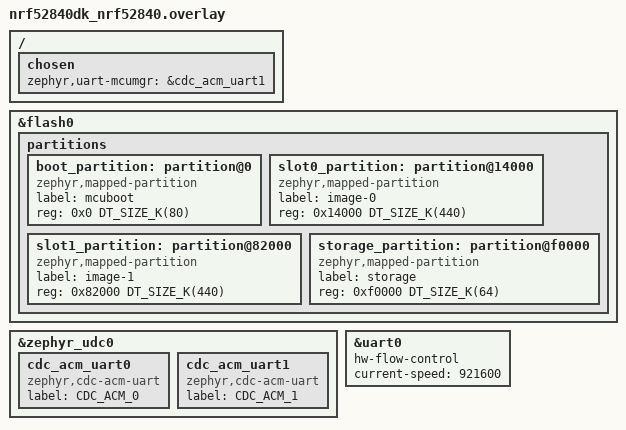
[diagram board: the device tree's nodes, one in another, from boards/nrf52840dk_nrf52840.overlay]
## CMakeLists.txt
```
# BLE bridge firmware (Task 9 data plane, Task 10 BLE central).
#
# Reuses the C frame library in ../proto (Task 6) verbatim via
# add_subdirectory(); only bridge_status_t was appended to bridge_proto.h.
#
# Pure-logic units (bridge_dispatch.c, bridge_info.c, bridge_ble_pure.c)
# deliberately include NO Zephyr headers - only the standard headers plus
# bridge_proto.h - so they compile as a standalone host target for
# host-side unit tests later (ADR-005 style):
#
#     cc -std=c11 -Wall -Wextra -I firmware/proto \
#        -c firmware/app/src/bridge_dispatch.c \
#        -c firmware/app/src/bridge_ble_pure.c \
#        -c firmware/app/src/bridge_info.c -c firmware/proto/bridge_proto.c

cmake_minimum_required(VERSION 3.20.0)

# ---- Bridge version, single bump point (D3, task-dfu-a report §9.5) -------
# BRIDGE_VERSION_STR is the ONE place to bump: "maj.min.rev[-suffix]".
#   - numeric maj.min.rev -> MCUboot image header version (imgtool --version,
#     "maj.min.rev+build": imgtool rejects non-numeric build counters, so a
#     pre-release suffix like "-dfu-test" rides in the ping string only);
#   - full string (suffix included) -> CONFIG_BRIDGE_VERSION (bridge ping
#     "blebridge<version>") through the APPVERSION Kconfig default.
# The injection happens at the Kconfig stage (env exported to kconfig.py by
# zephyr/cmake/modules/kconfig.cmake:156-159) because the signing script that
# finally reads CONFIG_MCUBOOT_IMGTOOL_SIGN_VERSION
# (nrf/cmake/sysbuild/image_signing.cmake:88) is included from INSIDE
# find_package(Zephyr) -> zephyr/CMakeLists.txt:2203; anything a CMakeLists
# sets after find_package is too late.  Upstream never exports the guard
# variable VERSION_MAJOR (zephyr/modules/Kconfig.mcuboot:111), which is why
# the imgtool-version default stayed "0.0.0+0" - exported here to engage it.
#
# NOTE: -DCONFIG_BRIDGE_VERSION=<s> still overrides the ping string alone
# (Kconfig CLI precedence) but then the ping string and the image header
# version decouple.  sysbuild does not forward arbitrary -D variables to the
# image builds, so the bump path is editing BRIDGE_VERSION_STR above (a
# non-sysbuild single-image `west build -DBRIDGE_VERSION_STR=...` works too).
set(BRIDGE_VERSION_STR "0.6.3" CACHE STRING
    "bridge version, maj.min.rev with optional -suffix")
string(REGEX MATCH "^([0-9]+)\\.([0-9]+)\\.([0-9]+)(-.*)?$"
       _bridge_semver "${BRIDGE_VERSION_STR}"
)
if(NOT _bridge_semver)
  message(FATAL_ERROR
    "BRIDGE_VERSION_STR (\"${BRIDGE_VERSION_STR}\") must be numeric "
    "maj.min.rev with an optional -suffix (D3: it also forms the MCUboot "
    "image header version)."
  )
endif()
set(APP_VERSION_STRING "${BRIDGE_VERSION_STR}")
set(APP_VERSION_TWEAK_STRING
    "${CMAKE_MATCH_1}.${CMAKE_MATCH_2}.${CMAKE_MATCH_3}+0")
set(ENV{VERSION_MAJOR} "${CMAKE_MATCH_1}")

find_package(Zephyr REQUIRED HINTS $ENV{ZEPHYR_BASE})
project(bridge_bridge LANGUAGES C)

set(BRIDGE_PROTO_DIR ${CMAKE_CURRENT_SOURCE_DIR}/../proto)
add_subdirectory(${BRIDGE_PROTO_DIR} proto_build)

target_link_libraries(app PRIVATE bridge_proto)
target_include_directories(app PRIVATE src)

target_sources(app PRIVATE
  src/main.c
  src/bridge_phy.c
  src/bridge_link.c
  src/bridge_dispatch.c
  src/bridge_info.c
  src/bridge_ble.c
  src/bridge_ble_pure.c
  src/bridge_periph.c
)

# BRIDGE_PHY is a string Kconfig ("cdc" | "uart0"); map it onto a single
# compile definition so the C sources can select at compile time (C
# preprocessor cannot compare strings).
if(CONFIG_BRIDGE_PHY STREQUAL "uart0")
  target_compile_definitions(app PRIVATE BRIDGE_PHY_MODE_UART0=1)
else()
  if(NOT CONFIG_BRIDGE_PHY STREQUAL "cdc")
    message(FATAL_ERROR "CONFIG_BRIDGE_PHY must be \"cdc\" or \"uart0\", got \"${CONFIG_BRIDGE_PHY}\"")
  endif()
  target_compile_definitions(app PRIVATE BRIDGE_PHY_MODE_CDC=1)
endif()

# Self-imposed warning hygiene for the new sources (Zephyr already adds
# -Wall; -Wextra is our own bar for this app).
target_compile_options(app PRIVATE -Wall -Wextra)

# NOTE for anyone trying to set CONFIG_MCUBOOT_IMGTOOL_SIGN_VERSION here
# (after find_package): that CMake variable is consumed by the signing script
# while find_package(Zephyr) is still running (see the version block at the
# top of this file for the working injection point and the full story).
```

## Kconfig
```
# BLE bridge firmware application options (Task 9).

mainmenu "BLE bridge firmware"

menu "bridge options"

config BRIDGE_PHY
	string "bridge physical layer"
	default "cdc"
	help
	  "cdc"   = nRF52840 native USB CDC ACM on zephyr_udc0 (primary,
	            ADR-002 revision 1; bit rate is negotiated by USB).
	  "uart0" = DK UART0 at 921600 8N1 with RTS/CTS hardware flow
	            control (backup, external adapter; pins P0.06/P0.08/
	            P0.05/P0.07 as wired by the nrf52840dk board files).
	  Anything else fails the CMake configure step.

config BRIDGE_VERSION
	string "bridge semantic version (ping body is blebridge<version>)"
	default "$(APPVERSION)"
	help
	  Derived from BRIDGE_VERSION_STR in CMakeLists.txt (the single bump
	  point, D3): the Kconfig environment exports APPVERSION from it at
	  configure time.  Bump the CMake variable, not this default.

config BRIDGE_CREDITS_INIT
	int "initial event credit balance (host grants more via CMD.credits)"
	default 128

config BRIDGE_LOG_LEVEL
	int "initial log level for EVT.DEBUG gating (0=off 1=err 2=warn 3=info 4=debug)"
	default 3
	range 0 4

config BRIDGE_USB_DTR_WAIT_MS
	int "max wait at boot for CDC ACM DTR before starting (ms)"
	default 5000

config BRIDGE_EVENT_PAYLOAD_MAX
	int "largest event payload accepted by bridge_link_post_event (bytes)"
	default 256

config BRIDGE_EVENT_QUEUE_LEN
	int "depth of the ISR-safe event queue feeding the event thread"
	default 16

config BRIDGE_TX_QUEUE_LEN
	int "depth of the TX frame queue drained by the single TX thread"
	default 8

config BRIDGE_CONNECT_TIMEOUT_MS
	int "max wait for CMD.connect to establish the link (ms)"
	default 5000

config BRIDGE_PAIR_TIMEOUT_MS
	int "max wait for CMD.pair to complete SMP pairing (ms)"
	default 8000
	range 500 30000

config BRIDGE_SCAN_DURATION_MS
	int "scan window used by CMD.scan_start when the request says 0 (ms)"
	default 8000
	range 100 60000

config BRIDGE_SCAN_FILTER_FEF5
	bool "EVT.SCAN reports only adverts carrying 0xFEF5 service data"
	default n
	help
	  Default off: every advert is reported and the host filters (daemon
	  keeps the dedup-by-addr view).  Turn on for a quiet wire.

config BRIDGE_SCAN_CACHE_SIZE
	int "scan result cache entries (connect-by-name lookups)"
	default 8
	range 1 64

config BRIDGE_GATT_CHAR_MAX
	int "characteristics cached per link across host-triggered discoveries"
	default 32
	range 1 32
	help
	  Entries of the GATT map filled by CMD.disc_svc (one run per service,
	  merged until the link drops; each characteristic's CCC descriptor
	  rides along inside its entry).  The SUOTA service needs 10; a
	  generic multi-service device wants headroom.

config BRIDGE_ADV_NAME
	string "local device name used by CMD.adv_start (FR-H)"
	default "blebridge"

config BRIDGE_ADV_INTERVAL_DEFAULT_MS
	int "advertising interval (ms) used by CMD.adv_start when the request sends 0xFFFF"
	default 100
	range 20 10240

config BRIDGE_ADV_AUTO_RESTART
	bool "automatically restart advertising after the peripheral link drops (FR-H fix round 1)"
	default y
	help
	  The advertising intent survives a lost peripheral link: a clean
	  disconnect or a crashed peer re-starts the last advertising
	  configuration when CMD.adv_start was in effect.  Only an explicit
	  CMD.adv_stop silences the auto-restart (real-device finding
	  2026-09-25: every link loss otherwise required a manual adv-start).

config BRIDGE_GATT_DYN_SVCS
	int "host-defined GATT service slots (CMD.gatt_define, FR-H5)"
	default 4
	range 1 8

config BRIDGE_GATT_DYN_CHARS_MAX
	int "characteristics per host-defined GATT service (CMD.gatt_define)"
	default 8
	range 1 8

config BRIDGE_GATT_DYN_SVC_POOL
	int "value-storage bytes per host-defined GATT service slot"
	default 1024
	range 64 4096
	help
	  Sum of all characteristic max_len values of ONE gatt_define
	  service; the definition is rejected when the request exceeds it.

config BRIDGE_CONFIRM_DELAY_MS
	int "stable-uptime milliseconds required before image self-confirm"
	default 10000
	range 1000 600000
	help
	  The confirm thread (main.c) waits this long after boot, checks the
	  bridge health counters, and only then calls
	  boot_write_img_confirmed().  An image that crashes or wedges before
	  the deadline never confirms, so the next reset makes MCUboot swap
	  back to the previous slot (revert).  Keep this well above any
	  plausible boot-time failure window but short enough that a normal
	  boot confirms without host interaction.

config BRIDGE_CONFIRM_THREAD_STACK
	int "stack bytes for the self-confirm thread"
	default 1024
	range 512 8192

endmenu

source "Kconfig.zephyr"
```

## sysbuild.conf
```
# Self-OTA (task-dfu-a): sysbuild + MCUboot dual-slot baseline.
#
# Eval report docs/reports/dfu-usbcdc-eval-20260926.md §6.1.  Enabling the
# bootloader switches the build to NCS sysbuild mode.  Partition freeze,
# NCS v3.4.1 finding: on nrf52840dk this NCS does NOT engage the Nordic
# partition manager -- the layout comes from the devicetree fixed
# partitions (zephyr/dts/vendor/nordic/nrf52840_partition.dtsi).  The
# reproducible "frozen" layout is therefore the committed overlay pair
#   - boards/nrf52840dk_nrf52840.overlay  (app; sysbuild.conf also makes
#     a plain `west build` a sysbuild build, so this map covers ALL builds)
#   - sysbuild/mcuboot.overlay            (bootloader, same map)
# which must stay byte-consistent; see those files for the measured 48K vs
# 80K decision (serial recovery needs ~60 KiB).
#
# Upgrade mode: MCUBOOT_MODE_SWAP_USING_MOVE (the NCS choice default in
# nrf/sysbuild/Kconfig.mcuboot; sibling of swap-using-scratch/offset).  Both
# non-scratch swap modes keep the "trial + confirm + revert" semantics that
# is the brick-proof core: an unconfirmed image is swapped back by MCUboot
# on the next reset.  nRF52840 has uniform 4 KB pages (nrf52840.dtsi
# erase-block-size), which satisfies the homogeneous-page requirement of
# offset/move; no scratch partition is needed.  Kept at the default instead
# of pinning a mode: the default tracks NCS recommendations across releases.
# (Verified in build-dfu/mcuboot/zephyr/.config: BOOT_SWAP_USING_MOVE=y,
# SINGLE_APPLICATION_SLOT unset, UPDATEABLE_IMAGE_NUMBER=1.)
#
# Signature: BOOT_SIGNATURE_TYPE_ECDSA_P256 is already the sysbuild default
# for nRF52840 (nrf/sysbuild/Kconfig.mcuboot BOOT_SIGNATURE_TYPE choice).
# The signing key is user-generated (NOT committed; see ci/keys/ -- generate
# with: openssl ecparam -name prime256v1 -genkey -noout -out <key>.pem).
# The key path must be absolute or relative to the app config dir /
# west topdir (zephyr/cmake/mcuboot.cmake resolution order), so tools/
# build-dfu.sh injects it as an absolute -DSB_CONFIG_BOOT_SIGNATURE_KEY_FILE.
# A plain `west build` without that flag falls back to the MCUboot tree's
# root-ec-p256.pem test key: the build succeeds but the images would not be
# verifiable by a bootloader built with your key -- always build
# through tools/build-dfu.sh for anything that gets flashed.
SB_CONFIG_BOOTLOADER_MCUBOOT=y
# One merged hex per board target (mcuboot + app slots): the artifact
# WCH-Link/pyocd flashes for the whole-image bring-up.
SB_CONFIG_MERGED_HEX_FILES=y
```

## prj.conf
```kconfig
# BLE bridge firmware (Task 9 data plane, Task 10 BLE central) - nrf52840dk/nrf52840
#
# Data plane: USB CDC ACM (primary) / UART0 (backup), framing + dispatch +
# credit flow control.  Zephyr LOG is intentionally OFF: the bridge has its
# own EVT.DEBUG log channel on the protocol stream.

CONFIG_SERIAL=y
CONFIG_UART_INTERRUPT_DRIVEN=y
CONFIG_UART_LINE_CTRL=y
CONFIG_RING_BUFFER=y

# CMD.reset performs sys_reboot(SYS_REBOOT_COLD) after the best-effort ACK.
CONFIG_REBOOT=y

# Native USB device stack (new stack, Zephyr 4.x) + CDC ACM class.
CONFIG_USB_DEVICE_STACK_NEXT=y
CONFIG_USBD_CDC_ACM_CLASS=y
CONFIG_CDC_ACM_SERIAL_INITIALIZE_AT_BOOT=n
CONFIG_HWINFO=y

# The protocol stream owns cdc_acm_uart0 end to end: no Zephyr
# console/printk sink and no LOG subsystem on the same UART (the bridge's
# log channel is EVT.DEBUG on the protocol stream itself).  Threads are the
# whole app.
# task-dfu-a: CONFIG_CONSOLE flips to y because MCUMGR_TRANSPORT_UART
# depends on CONSOLE (zephyr/subsys/mgmt/mcumgr/transport/Kconfig.uart:20).
# UART_CONSOLE stays n -- no console backend attaches anywhere, so nothing
# ever writes to either CDC port except the bridge protocol (port 0) and
# the SMP transport (port 1); the flip is a dependency formality verified
# by the crosstalk regression in the task report.
CONFIG_CONSOLE=y
CONFIG_UART_CONSOLE=n
CONFIG_LOG=n
CONFIG_MULTITHREADING=y

# Skeleton hygiene: asserts on, thread names for debugging, hex artifact
# for the build gate report.CONFIG_ASSERT=y
CONFIG_THREAD_NAME=y
CONFIG_BUILD_OUTPUT_HEX=y

# ---- BLE central (Task 10; symbol names verified against NCS v3.4.1) ----
CONFIG_BT=y
CONFIG_BT_CENTRAL=y
# FR-H multi-role: 1 central (host-initiated device link) + 1 peripheral
# (phone/tool connecting to the bridge's own services) concurrently.
CONFIG_BT_MAX_CONN=2

# ---- BLE peripheral (FR-H) ----
# GATT server role: the preset 0xFFE0 test service (compile-time) plus
# host-defined services via CMD.gatt_define (runtime registration).
CONFIG_BT_PERIPHERAL=y
CONFIG_BT_GATT_DYNAMIC_DB=y

# GATT client operations + automatic ATT MTU exchange on connect (works for
# the central role too; verified against NCS v3.4.1 / Zephyr 4.4.2).
CONFIG_BT_GATT_CLIENT=y
CONFIG_BT_GATT_AUTO_UPDATE_MTU=y

# 244-byte characteristic payloads: local ATT MTU halves are
#   TX = CONFIG_BT_L2CAP_TX_MTU (247)
#   RX = CONFIG_BT_BUF_ACL_RX_SIZE - 4 (247)
# and the buffers must carry the 4-byte L2CAP header + 247 ATT bytes.
CONFIG_BT_L2CAP_TX_MTU=247
CONFIG_BT_BUF_ACL_TX_SIZE=251
CONFIG_BT_BUF_ACL_RX_SIZE=251

# Buffer counts: 244-byte notify bursts arrive as up to 10 ACL fragments;
# defaults (TX 3) would congest.  RX pool = BT_MAX_CONN + 1 + EXTRA.
# HCI event buffers must stay above the ACL TX count (build-time assert).
CONFIG_BT_BUF_ACL_TX_COUNT=10
CONFIG_BT_BUF_ACL_RX_COUNT_EXTRA=6
CONFIG_BT_BUF_EVT_RX_COUNT=12

# Data Length Update + 2M PHY on connect (central preference; SDC has no
# separate "enable 2M" switch - docs/research/nordic-stack-eval.md).
CONFIG_BT_DATA_LEN_UPDATE=y
CONFIG_BT_AUTO_DATA_LEN_UPDATE=y
CONFIG_BT_PHY_UPDATE=y
CONFIG_BT_AUTO_PHY_CENTRAL_2M=y
CONFIG_BT_USER_PHY_UPDATE=y

# Nordic GATT Discovery Manager (NCS): 0xFEF5 discovery at connect.  Runs
# on the system workqueue (saves the dedicated workq thread), map sized for
# the SUOTA service.
CONFIG_BT_GATT_DM=y
CONFIG_BT_GATT_DM_WORKQ_SYS=y
CONFIG_BT_GATT_DM_MAX_ATTRS=64

# bt_gatt_dm allocates the discovered attr array from the system heap, but
# the module only adds 512B of its own (HEAP_MEM_POOL_ADD_SIZE_BT_GATT_DM).
# A full 0xFEF5 service (~25 attrs) needs more: with the default heap of
# 0 the dm fails with -ENOMEM (-12) exactly when the service IS found
# (random devices without 0xFEF5 mask this - bring-up 2026-09-25).
CONFIG_HEAP_MEM_POOL_SIZE=4096

# Host create timeout must bracket CONFIG_BRIDGE_CONNECT_TIMEOUT_MS (5 s).
CONFIG_BT_CREATE_CONN_TIMEOUT=5

# ---- SMP pairing/encryption (FR-B5) ----
# Session-scoped LE pairing so the host can raise the link to L2 (Just Works:
# the stack reports NoInputNoOutput when no auth callbacks provide IO -- smp.c
# get_io_capa(); unauthenticated pairing, L2 encryption only).
CONFIG_BT_SMP=y
# Bond persistence (settings/FS) is deliberately out of FR-B5 scope: keys live
# in RAM for the session only; a serial CMD.reset drops them.  (Explicit over
# implicit: default is n; flipping it later needs SETTINGS + an NVS backend.)
CONFIG_BT_SETTINGS=n
# FR-H peripheral likewise runs unencrypted/unpaired: the test services are
# plain-text by design (no bond, no SETTINGS backend needed).

# ---- Self-OTA infrastructure (task-dfu-a) --------------------------------
# CONFIG_BOOTLOADER_MCUBOOT is intentionally NOT set here: sysbuild injects
# it into the app image when SB_CONFIG_BOOTLOADER_MCUBOOT=y
# (zephyr/share/sysbuild/image_configurations/MAIN_image_default.cmake:8),
# and setting it unconditionally would wrongly header-offset the legacy
# single-slot flow (tools/flash.sh) which links at 0x0 without a
# bootloader.  The dual-slot partition map (80K bootloader variant) lives
# in boards/nrf52840dk_nrf52840_dfu80.overlay, applied by build-dfu.sh.
# IMG_MANAGER depends on STREAM_FLASH (zephyr/subsys/dfu/Kconfig:8) and
# MCUBOOT_IMG_MANAGER depends on FLASH_MAP -- all requested explicitly,
# exactly like the smp_svr authority sample (FLASH=y is also its first
# entry; omitting it makes STREAM_FLASH_INSPECT y-select FLASH_PAGE_LAYOUT
# whose FLASH dependency fails -> Kconfig warning-as-error).
CONFIG_FLASH=y
CONFIG_STREAM_FLASH=y
CONFIG_FLASH_MAP=y
CONFIG_IMG_MANAGER=y
CONFIG_IMG_ERASE_PROGRESSIVELY=y

# MCUmgr SMP over the second CDC ACM (zephyr,uart-mcumgr = &cdc_acm_uart1).
# Transport deps (Kconfig.uart): CONSOLE (flipped above), BASE64, CRC,
# UART_MCUMGR.  Auth is deliberately absent (intratable internal tool on a
# lab USB link; the group set below is image upload/test/confirm + os
# reset -- the minimum for the DFU loop).
CONFIG_UART_MCUMGR=y
# MCUMGR depends on NET_BUF + ZCBOR (subsys/mgmt/mcumgr/Kconfig:7-8);
# both explicit like the smp_svr authority sample.
CONFIG_NET_BUF=y
CONFIG_ZCBOR=y
CONFIG_MCUMGR=y
CONFIG_MCUMGR_TRANSPORT_UART=y
# Frame MTU 1024 (<= MCUMGR_TRANSPORT_NETBUF_SIZE+2; NETBUF raised from the
# 384 default so the relation holds).  4 netbufs x 1024 B ~= 4 KB RAM.
CONFIG_MCUMGR_TRANSPORT_UART_MTU=1024
CONFIG_MCUMGR_TRANSPORT_NETBUF_SIZE=1024
CONFIG_BASE64=y
CONFIG_CRC=y
CONFIG_MCUMGR_GRP_IMG=y
CONFIG_MCUMGR_GRP_OS=y

# Application self-confirmation: RETENTION_BOOT_MODE exposes bootmode_set()
# for CMD.enter_dfu (GPREGRET -> MCUboot serial recovery); the chosen
# zephyr,boot-mode node lives in the board file (boot_mode0 under gpregret1).
# Dependency chain to spell out (all three, or the tail silently drops to n):
# RETAINED_MEM -> RETENTION -> RETENTION_BOOT_MODE; the GPREGRET retained-mem
# driver defaults on once RETAINED_MEM is y (DT_HAS_NORDIC_NRF_GPREGRET).
CONFIG_RETAINED_MEM=y
CONFIG_RETENTION=y
CONFIG_RETENTION_BOOT_MODE=y

# The confirm thread (main.c) waits BRIDGE_CONFIRM_DELAY_MS of stable
# uptime, checks bridge health counters, then boot_write_img_confirmed().
# A image that dies before that point is reverted by MCUboot on reset.
CONFIG_MAIN_STACK_SIZE=3072
CONFIG_BRIDGE_CONFIRM_DELAY_MS=10000
CONFIG_BRIDGE_CONFIRM_THREAD_STACK=1024
```

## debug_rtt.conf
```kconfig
# Bring-up diagnostics: Zephyr log over SEGGER RTT (SWD), does not touch UART0 pins.
# 用法: 构建 -DEXTRA_CONF_FILE=<repo>/firmware/app/debug_rtt.conf;
#       烧录 pyocd flash -e sector -t nrf52840 -f 1000000 <hex>（WCH-Link 限 1MHz SWD）。
CONFIG_LOG=y
CONFIG_LOG_MODE_MINIMAL=y
CONFIG_USE_SEGGER_RTT=y
CONFIG_RTT_CONSOLE=y
CONFIG_CONSOLE=y
```

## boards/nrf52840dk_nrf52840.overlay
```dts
/*
 * blebridge bridge overlay for nrf52840dk/nrf52840 (Task 9, rev. task-dfu-a).
 *
 * - zephyr_udc0 (native nRF52840 USB device, already status-okay in the
 *   board file) gains the CDC ACM UART class instance: the primary
 *   physical layer, selected with CONFIG_BRIDGE_PHY="cdc".
 * - task-dfu-a: a second CDC ACM instance (cdc_acm_uart1) serves the
 *   MCUmgr SMP transport, chosen via zephyr,uart-mcumgr (A1 dual-CDC
 *   architecture, docs/reports/dfu-usbcdc-eval-20260926.md §3.1).  The
 *   bridge protocol keeps owning cdc_acm_uart0 end to end; the SMP
 *   transport binds cdc_acm_uart1 exclusively (smp_uart.c), so the two
 *   streams cannot cross-contaminate.  macOS enumerates the pair as two
 *   /dev/cu.usbmodem* ports (same device, interface 0 = bridge, 1 = SMP).
 * - task-dfu-a: DFU dual-slot partition map, 80 KB bootloader variant.
 *   Lives HERE (not a build-flag overlay) because sysbuild.conf makes
 *   EVERY build of this app a sysbuild build (auto-detected: plain
 *   `west build` produces _sysbuild + dfu_application.zip), so there is
 *   no single-slot consumer left and one map for all builds is the only
 *   way to keep ad-hoc flashes consistent with the on-board bootloader.
 *   Sizes = official smp_svr "larger_mcuboot" layout: measured
 *   MCUboot-with-serial-recovery is 60.1 KiB and does NOT fit the stock
 *   48 KB boot partition (eval report §3.2 risk, resolved by measurement).
 *   The bootloader child declares the IDENTICAL map in
 *   sysbuild/mcuboot.overlay -- the two files must never diverge (each
 *   image derives slot ends / swap trailers from its own devicetree).
 * - uart0 is reconfigured to 921600 8N1 with RTS/CTS hardware flow
 *   control as the backup physical layer (CONFIG_BRIDGE_PHY="uart0").
 *   The board pinctrl already maps TX=P0.06 RX=P0.08 RTS=P0.05 CTS=P0.07.
 *   Bit rate only matters in uart0 mode; USB negotiates its own speed.
 */

/delete-node/ &boot_partition;
/delete-node/ &slot0_partition;
/delete-node/ &slot1_partition;
/delete-node/ &storage_partition;

&flash0 {
	partitions {
		boot_partition: partition@0 {
			compatible = "zephyr,mapped-partition";
			label = "mcuboot";
			reg = <0x0 DT_SIZE_K(80)>;
		};

		slot0_partition: partition@14000 {
			compatible = "zephyr,mapped-partition";
			label = "image-0";
			reg = <0x14000 DT_SIZE_K(440)>;
		};

		slot1_partition: partition@82000 {
			compatible = "zephyr,mapped-partition";
			label = "image-1";
			reg = <0x82000 DT_SIZE_K(440)>;
		};

		storage_partition: partition@f0000 {
			compatible = "zephyr,mapped-partition";
			label = "storage";
			reg = <0xf0000 DT_SIZE_K(64)>;
		};
	};
};

/* The cdc_acm_uart1 phandle is referenced by the chosen below; declare it
 * "cdc_acm_uart1: cdc_acm_uart1" (label + name), like the smp_svr
 * usb.overlay authority does for its CDC node. */

&zephyr_udc0 {
	status = "okay";

	cdc_acm_uart0: cdc_acm_uart0 {
		compatible = "zephyr,cdc-acm-uart";
		label = "CDC_ACM_0";
	};

	cdc_acm_uart1: cdc_acm_uart1 {
		compatible = "zephyr,cdc-acm-uart";
		label = "CDC_ACM_1";
	};
};

/ {
	chosen {
		zephyr,uart-mcumgr = &cdc_acm_uart1;
	};
};

&uart0 {
	hw-flow-control;
	current-speed = <921600>;
};
```

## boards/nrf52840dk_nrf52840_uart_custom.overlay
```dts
/*
 * blebridge bridge — 用户自定义 UART0 引脚 overlay（nrf52840dk/nrf52840）。
 *
 * 背景: 固件跑在 nrf52840dk/nrf52840 目标码上，但实际载板为用户自制板，
 * UART0 不走 DK 原生排布，而是走 P1 口。映射逐字采用用户选定的引脚:
 *
 *   信号  引脚    对应 DK 默认（boards/nrf52840dk_nrf52840.overlay /
 *                       板级 pinctrl dtsi）
 *   TX   = P1.04  (DK: P0.06)
 *   RX   = P1.13  (DK: P0.08)
 *   RTS  = P1.15  (DK: P0.05)
 *   CTS  = P1.00  (DK: P0.07)
 *
 * 速率/模式与 DK 默认路径一致: 921600 8N1 + RTS/CTS 硬件流控
 * （备用物理层，CONFIG_BRIDGE_PHY="uart0" 时启用）。
 *
 * 偏置选择（用户板上下文）:
 *   RX  bias-pull-up   —— 对端未接线/未上电时 RX 空闲保持高（UART 空闲电平）。
 *   CTS bias-pull-down —— CTS 悬空时读低 = 允许发送: 为 2 线（仅 TX/RX）
 *                         升级路径留门，不接流控线也能发。
 *
 * 使用: app 目标构建时附加
 *   -DEXTRA_DTC_OVERLAY_FILE=boards/nrf52840dk_nrf52840_uart_custom.overlay
 * 或 tools/flash.sh app --uart-custom（独立 build-t10-uart-custom 目录）。
 * 不修改、不影响 DK 默认 overlay（boards/nrf52840dk_nrf52840.overlay，
 * P0.06/08/05/07）—— 默认构建/HIL 不带本文件时行为与原先完全一致。
 */

&pinctrl {
	uart0_default_alt: uart0_default_alt {
		group1 {
			psels = <NRF_PSEL(UART_TX, 1, 4)>,
				<NRF_PSEL(UART_RTS, 1, 15)>;
		};

		group2 {
			psels = <NRF_PSEL(UART_RX, 1, 13)>;
			bias-pull-up;
		};

		group3 {
			psels = <NRF_PSEL(UART_CTS, 1, 0)>;
			bias-pull-down;
		};
	};

	uart0_sleep_alt: uart0_sleep_alt {
		group1 {
			psels = <NRF_PSEL(UART_TX, 1, 4)>,
				<NRF_PSEL(UART_RX, 1, 13)>,
				<NRF_PSEL(UART_RTS, 1, 15)>,
				<NRF_PSEL(UART_CTS, 1, 0)>;
			low-power-enable;
		};
	};
};

&uart0 {
	pinctrl-0 = <&uart0_default_alt>;
	pinctrl-1 = <&uart0_sleep_alt>;
	pinctrl-names = "default", "sleep";
	hw-flow-control;
	current-speed = <921600>;
};
```

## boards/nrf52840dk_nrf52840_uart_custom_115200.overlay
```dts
/*
 * blebridge bridge — bring-up 变体: 用户自定义 UART 引脚 @ 115200 8N1 + RTS/CTS。
 *
 * 与 nrf52840dk_nrf52840_uart_custom.overlay（产品速率 921600, FR-A5）唯一的
 * 差别是 current-speed = <115200>。存在理由（2026-09-25 bring-up 实测）:
 * 当前唯一 host 通路是 WCH-Link 的 CDC UART 桥,其 921600 RX 方向对 >64 B
 * 长突发不可靠（字节丢失/乱序, ≤64 B 帧始终完好）,长帧 CRC 无法通过;
 * 115200 下长帧 CRC 全部通过。待 host 通路更换或桥固件验证 921600 后,
 * 产品配置仍回到 921600 overlay。
 *
 * 引脚与偏置逐字沿用产品 overlay:
 *   TX=P1.04 (pull 无)  RX=P1.13 (pull-up)
 *   RTS=P1.15           CTS=P1.00 (pull-down, 悬空=允许发送)
 *
 * 使用（独立 build 目录, 不污染产品构建）:
 *   west build -p -b nrf52840dk/nrf52840 <app> -d <scratch> -- \
 *       '-DCONFIG_BRIDGE_PHY="uart0"' \
 *       -DEXTRA_DTC_OVERLAY_FILE=<repo>/firmware/app/boards/nrf52840dk_nrf52840_uart_custom_115200.overlay \
 *       -DEXTRA_CONF_FILE=<repo>/firmware/app/debug_rtt.conf
 * 烧录: pyocd flash -e sector -t nrf52840 -f 1000000 <hex>（WCH-Link 限 1MHz SWD）
 * host: SerialTransport(baudrate=115200, rtscts=False)（macOS CDC 上
 *       rtscts=True 会静默扣发 write; 开端口首帧会被桥毛刺打坏,需重试）
 */

&pinctrl {
	uart0_default_alt: uart0_default_alt {
		group1 {
			psels = <NRF_PSEL(UART_TX, 1, 4)>,
				<NRF_PSEL(UART_RTS, 1, 15)>;
		};

		group2 {
			psels = <NRF_PSEL(UART_RX, 1, 13)>;
			bias-pull-up;
		};

		group3 {
			psels = <NRF_PSEL(UART_CTS, 1, 0)>;
			bias-pull-down;
		};
	};

	uart0_sleep_alt: uart0_sleep_alt {
		group1 {
			psels = <NRF_PSEL(UART_TX, 1, 4)>,
				<NRF_PSEL(UART_RX, 1, 13)>,
				<NRF_PSEL(UART_RTS, 1, 15)>,
				<NRF_PSEL(UART_CTS, 1, 0)>;
			low-power-enable;
		};
	};
};

&uart0 {
	pinctrl-0 = <&uart0_default_alt>;
	pinctrl-1 = <&uart0_sleep_alt>;
	pinctrl-names = "default", "sleep";
	hw-flow-control;
	current-speed = <115200>;
};
```

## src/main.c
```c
/*
 * main.c - BLE bridge firmware entry point (Task 9 data plane,
 * Task 10 BLE central, task-dfu-a self-confirm).
 *
 * Bring-up order: physical layer -> BLE stack (bt_enable before the link
 * threads exist, so no command can outrun it; on failure the data plane
 * still comes up and the BLE family answers ERR_NOT_READY) -> link threads
 * -> boot EVT.DEBUG on the "sys" namespace -> confirm thread.
 *
 * Self-confirm (task-dfu-a): the confirm thread waits
 * CONFIG_BRIDGE_CONFIRM_DELAY_MS of stable uptime, takes the bridge health
 * snapshot and only then calls boot_write_img_confirmed().  MCUboot booted
 * this image as an unconfirmed "test" swap; if the image dies (or was
 * never healthy) before the confirm, the next reset swaps back to the
 * previous slot -- the brick-proof core of the A1+B architecture
 * (docs/reports/dfu-usbcdc-eval-20260926.md §4).
 */

#include <stdbool.h>
#include <stdio.h>

#include <zephyr/kernel.h>
#include <zephyr/dfu/mcuboot.h>

#include "bridge_ble.h"
#include "bridge_dispatch.h"
#include "bridge_link.h"
#include "bridge_phy.h"

#define CONFIRM_POLL_MS 1000

/* Latched in main() before the confirm thread starts: read-only for the
 * thread afterwards, no locking needed. */
static bool bringup_ok;

static K_THREAD_STACK_DEFINE(confirm_stack,
                             CONFIG_BRIDGE_CONFIRM_THREAD_STACK);
static struct k_thread confirm_thread;

static void confirm_thread_fn(void *a, void *b, void *c)
{
    ARG_UNUSED(a);
    ARG_UNUSED(b);
    ARG_UNUSED(c);

    const uint32_t min_uptime_s =
        (uint32_t)(CONFIG_BRIDGE_CONFIRM_DELAY_MS / 1000);

    for (;;) {
        k_sleep(K_MSEC(CONFIRM_POLL_MS));

        bool init_ok;
        uint32_t crc_errors;
        uint32_t tx_timeouts;
        uint32_t events_dropped;

        bridge_link_confirm_snapshot(&init_ok, &crc_errors, &tx_timeouts,
                                     &events_dropped);
        if (!init_ok) {
            init_ok = bringup_ok;
        }

        if (!bridge_confirm_ready((uint32_t)(k_uptime_get_32() / 1000U),
                                  min_uptime_s, init_ok, crc_errors,
                                  tx_timeouts, events_dropped)) {
            continue;
        }

        if (boot_is_img_confirmed()) {
            /* Reconfirmed boot of an already-confirmed image (or a build
             * without the MCUboot swap trailer): nothing to do. */
            return;
        }

        int err = boot_write_img_confirmed();
        uint8_t payload[64];
        char msg[48];

        int mlen = snprintf(msg, sizeof(msg), "img confirm %s (%d)",
                            (err == 0) ? "ok" : "FAIL", err);

        int plen = (mlen > 0)
                       ? bridge_evt_debug_build("sys", msg, payload,
                                                (uint16_t)sizeof(payload))
                       : -1;
        if (plen > 0) {
            (void)bridge_link_post_event(BRIDGE_EVT_DEBUG, payload,
                                         (uint16_t)plen);
        }
        if (err == 0) {
            return; /* confirmed: the thread's job is done */
        }
        /* Confirm write failed (I/O error): retry on the next poll; the
         * image stays unconfirmed (revert-on-reset remains armed). */
    }
}

int main(void)
{
    int err = bridge_phy_init();

    if (err != 0) {
        /* Bring-up failure: nothing to serve, park.  (MCUboot never gets a
         * confirm -> the next reset reverts to the previous slot.) */
        for (;;) {
            k_sleep(K_SECONDS(10));
        }
    }

    bool bt_ok = (bridge_ble_init() == 0);

    if (bt_ok) {
        /* CMD.reset drops the BLE link before rebooting. */
        bridge_link_set_reset_hook(bridge_ble_api()->shutdown);
    }

    err = bridge_link_init();
    if (err != 0) {
        for (;;) {
            k_sleep(K_SECONDS(10));
        }
    }
    bringup_ok = true;

    k_thread_create(&confirm_thread, confirm_stack,
                    K_THREAD_STACK_SIZEOF(confirm_stack), confirm_thread_fn,
                    NULL, NULL, NULL, 7, 0, K_NO_WAIT);
    k_thread_name_set(&confirm_thread, "bridge_confirm");

    uint8_t payload[64];
    char msg[48];

    int mlen = snprintf(msg, sizeof(msg), "boot %s %s", CONFIG_BRIDGE_VERSION,
                        bt_ok ? "bt" : "nobt");

    int plen = (mlen > 0) ? bridge_evt_debug_build("sys", msg, payload,
                                                   (uint16_t)sizeof(payload))
                          : -1;

    if (plen > 0) {
        (void)bridge_link_post_event(BRIDGE_EVT_DEBUG, payload,
                                     (uint16_t)plen);
    }
    return 0;
}
```

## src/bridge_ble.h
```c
/*
 * bridge_ble.h - BLE central bridge (Task 10): scan / connect / GATT
 * pass-through onto the bridge event channel.
 *
 * Thread model (task-10 brief):
 *   - Command-side functions (the bridge_ble_api_t table) run on the link
 *     RX thread and may block on semaphores with bounded timeouts.
 *   - Every Zephyr BT callback (scan recv, conn, gatt_dm, GATT completions,
 *     notifications) runs on BT-owned threads: it only touches state under
 *     the module lock, posts events through bridge_link_post_event() and
 *     gives semaphores - it never blocks and never touches the physical
 *     layer.
 *   - bt_conn reference discipline: bt_conn_le_create() hands over exactly
 *     one application reference held in `conn`; it is released exactly
 *     once - in the connected(err != 0) path or in disconnected().
 *   - Subscription params and all GATT op params are static (review red
 *     line: the stack keeps pointers into them across the async responses).
 *
 * Known limitation (task(12) final review, accepted): the module-local bare
 * `struct bt_conn *conn` is read/cleared from both the link RX thread and
 * the BT callback threads without a dedicated lock.  This is a data race in
 * the strict C11 sense; correctness rests on the Zephyr BT threading model
 * (all connection callbacks serialize on the BT RX work queue) and the
 * semaphore ordering around api_connect.  Hardening (RCU/lock or conn
 * handle indirection) is deferred to the post-L3 hardening task.
 */

#ifndef BRIDGE_BLE_H
#define BRIDGE_BLE_H

#include "bridge_ble_api.h"

#ifdef __cplusplus
extern "C" {
#endif

/**
 * Bring the BLE central up: bt_enable() + callback registration.  Call
 * once from main() before bridge_link_init() so no command can outrun it.
 *
 * @return 0 on success; the BLE api table then answers
 *         BRIDGE_STATUS_ERR_NOT_READY for every command.
 */
int bridge_ble_init(void);

/** The command surface handed to the dispatcher through the env. */
bridge_ble_api_t *bridge_ble_api(void);

#ifdef __cplusplus
}
#endif

#endif /* BRIDGE_BLE_H */
```

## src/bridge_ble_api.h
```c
/*
 * bridge_ble_api.h - function-pointer surface from the dispatcher to the
 * BLE central implementation (Task 10).
 *
 * Pure C11 (no Zephyr) so bridge_dispatch.c stays host-testable:
 *   - production (bridge_ble.c) provides the real table;
 *   - the firmware dispatcher receives it through bridge_dispatch_env_t;
 *   - a NULL table (host unit tests) keeps the Task 9 behaviour: every BLE
 *     command answers STATUS_ERR_NOT_READY.
 *
 * All functions are called on the link RX thread (the command dispatcher's
 * context) and may block internally on semaphores - the BLE callbacks they
 * wait for run on BT-owned threads and only use k_sem_give / atomics /
 * bridge_link_post_event().  Return values are bridge_status_t bytes
 * (bridge_proto.h): 0x00 = OK, anything else is reported to the host
 * verbatim as the response status byte.
 */

#ifndef BRIDGE_BLE_API_H
#define BRIDGE_BLE_API_H

#include <stddef.h>
#include <stdint.h>

#ifdef __cplusplus
extern "C" {
#endif

typedef struct bridge_ble_api {
    /** CMD.scan_start, payload u16 LE duration_ms (0 = firmware default). */
    uint8_t (*scan_start)(uint16_t duration_ms);

    /** CMD.scan_stop (no payload). */
    uint8_t (*scan_stop)(void);

    /**
     * CMD.connect, raw payload:
     *   1B mode (0 public addr / 1 random addr / 2 name) +
     *   mode 0/1: 6B address in displayed order ("AA:BB:.." -> AA BB ..)
     *   mode 2:   device name bytes (UTF-8)
     * Blocks until connected or timeout_ms elapsed.  On success the body
     * carries the resolved peer: 1B addr_type + 6B addr (displayed order).
     */
    uint8_t (*connect)(const uint8_t *payload, uint16_t len,
                       uint32_t timeout_ms, uint8_t *body, uint16_t cap,
                       uint16_t *body_len);

    /**
     * CMD.disconnect:
     *   - empty payload: drop the peripheral-role link when one exists
     *     (FR-H preference), otherwise the central link (legacy meaning);
     *   - 1B addr_type + 6B addr (displayed order): drop whichever link
     *     matches that peer address.
     * Async: the response only reflects submission; EVT.DISC arrives via
     * callback with the role byte telling the links apart.
     */
    uint8_t (*disconnect)(const uint8_t *payload, uint16_t len);

    /** CMD.mtu (no payload): current negotiated ATT MTU (23 before/between). */
    uint8_t (*mtu_get)(uint16_t *out_mtu);

    /**
     * CMD.gatt_read, uuid16 addressing: payload u16 LE uuid16; the
     * characteristic must be in the map (host-triggered discovery).
     */
    uint8_t (*gatt_read)(uint16_t uuid16, uint8_t *data, uint16_t cap,
                         uint16_t *data_len);

    /** CMD.gatt_read handle addressing: raw attribute handle, no map. */
    uint8_t (*gatt_read_handle)(uint16_t handle, uint8_t *data, uint16_t cap,
                                uint16_t *data_len);

    /** CMD.gatt_write, uuid16 addressing (see gatt_read). */
    uint8_t (*gatt_write)(uint8_t wtype, uint16_t uuid16,
                          const uint8_t *data, uint16_t len);

    /** CMD.gatt_write handle addressing: wtype + raw handle + value. */
    uint8_t (*gatt_write_handle)(uint8_t wtype, uint16_t handle,
                                 const uint8_t *data, uint16_t len);

    /** CMD.subscribe / CMD.unsubscribe, uuid16 addressing. */
    uint8_t (*subscribe)(uint16_t uuid16);
    uint8_t (*unsubscribe)(uint16_t uuid16);

    /**
     * CMD.subscribe handle addressing: subscribe the characteristic value
     * at `value_handle` by writing its CCCD at `cccd_handle` (notification
     * value 0x0001; no property check is possible without the map).
     */
    uint8_t (*subscribe_handle)(uint16_t value_handle, uint16_t ccc_handle);

    /** CMD.unsubscribe handle addressing: value handle of the subscription. */
    uint8_t (*unsubscribe_handle)(uint16_t value_handle);

    /**
     * CMD.disc_svc (generic bridge): run bt_gatt_dm for the 16-bit service
     * UUID `svc_uuid16` NOW and merge every discovered characteristic into
     * the map (uuid16 -> value/CCC handles, 128-bit UUIDs keyed by their
     * SIG prefix).  `svc_uuid16 == 0` re-discovers the last successfully
     * discovered service (NOT_READY when there is none yet).  On success
     * *nchars carries the number of characteristics found in THIS run.
     * The firmware never discovers or disconnects on its own.
     */
    uint8_t (*disc_svc)(uint16_t svc_uuid16, uint16_t *nchars);

    /**
     * CMD.pair (FR-B5): run SMP pairing on the current link and block until
     * the procedure settles (security level >= L2) or fails/times out.
     * On success the body carries 2 bytes: [0] = 1 when the link is
     * encrypted (bt_conn_enc_key_size() > 0), [1] = the resulting security
     * level (bt_conn_get_security()).  Failure answers
     * BRIDGE_STATUS_ERR_PAIR_FAILED.
     */
    uint8_t (*pair)(uint8_t *body, uint16_t cap, uint16_t *body_len);

    /**
     * CMD.conn_update: LE connection parameter update (1.25 ms interval /
     * 10 ms timeout units, BT_LE_CONN_PARAM encoding).  Async: the response
     * only reflects the request submission; the settled parameters are
     * reported on EVT.DEBUG by le_param_updated.
     */
    uint8_t (*conn_update)(uint16_t interval_min, uint16_t interval_max,
                           uint16_t latency, uint16_t timeout);

    /**
     * CMD.phy: LE PHY preference, 1 = 1M, 2 = 2M (both directions).
     * Async: the result is reported on EVT.DEBUG by le_phy_updated.
     */
    uint8_t (*phy_update)(uint8_t phy);

    /**
     * CMD.adv_start (FR-H): start connectable advertising for the locally
     * served GATT services.  `interval_ms` in ms, 0xFFFF = firmware
     * default; `name_on` includes the complete local name.  Already
     * advertising = idempotent OK.
     */
    uint8_t (*adv_start)(uint16_t interval_ms, uint8_t name_on);

    /** CMD.adv_stop (FR-H): stop advertising (idempotent). */
    uint8_t (*adv_stop)(void);

    /**
     * CMD.notify (FR-H): push `data` as notification content of a locally
     * served characteristic and notify subscribed peers.  `mode` 0 = the
     * preset notify characteristic, 1 = address by char `uuid16`.
     * NOT_READY (0x74) when no peer is subscribed.
     */
    uint8_t (*notify)(uint8_t mode, uint16_t uuid16, const uint8_t *data,
                      uint16_t len);

    /**
     * CMD.set_char (FR-H): update a locally served characteristic's value
     * (what peers read back); never touches the air.  Same `mode` rules as
     * notify; mode 0 targets the preset write characteristic.
     */
    uint8_t (*set_char)(uint8_t mode, uint16_t uuid16, const uint8_t *data,
                        uint16_t len);

    /**
     * CMD.gatt_define (FR-H5): register or replace one host-defined GATT
     * service; the raw payload is parsed by the peripheral module and the
     * success body carries the service base handle (2B LE).  BUSY while a
     * peripheral-role link is up.
     */
    uint8_t (*gatt_define)(const uint8_t *payload, uint16_t len,
                           uint8_t *body, uint16_t cap, uint16_t *body_len);

    /** Best-effort teardown before CMD.reset reboots (link reset hook). */
    void (*shutdown)(void);
} bridge_ble_api_t;

#ifdef __cplusplus
}
#endif

#endif /* BRIDGE_BLE_API_H */
```

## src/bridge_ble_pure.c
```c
/*
 * bridge_ble_pure.c - pure logic of the BLE central bridge (Task 10).
 * See bridge_ble_pure.h for the wire-format contract.
 */

#include "bridge_ble_pure.h"

#include <string.h>

#define SUOTA_SERVICE_UUID16 0xFEF5U

/* ---- advertisement parser ------------------------------------------------ */

int bridge_ble_adv_parse(const uint8_t *adv, size_t len, char *name_out,
                         size_t name_cap)
{
    int flags = 0;
    size_t pos = 0U;

    while (pos + 1U < len) { /* len byte + at least the type byte left */
        uint8_t field_len = adv[pos];

        if (field_len == 0U || pos + 1U + (size_t)field_len > len) {
            break; /* malformed/truncated: stop walking, keep what we have */
        }
        uint8_t type = adv[pos + 1U];
        const uint8_t *data = &adv[pos + 2U];
        size_t data_len = (size_t)field_len - 1U;

        if (type == 0x08U || type == 0x09U) { /* short / complete name */
            size_t n = data_len;

            if (name_out != NULL && name_cap > 0U) {
                if (n > name_cap - 1U) {
                    n = name_cap - 1U;
                }
                memcpy(name_out, data, n);
                name_out[n] = '\0';
            }
            flags |= BRIDGE_ADV_FLAG_NAME;
        } else if (type == 0x16U && data_len >= 2U) { /* service data */
            if (bridge_ble_get_le16(data) == SUOTA_SERVICE_UUID16) {
                flags |= BRIDGE_ADV_FLAG_SVC_FEF5;
            }
        }
        pos += 1U + (size_t)field_len;
    }
    return flags;
}

/* ---- scan cache ----------------------------------------------------------- */

void bridge_ble_scan_cache_init(bridge_scan_cache_t *c)
{
    memset(c, 0, sizeof(*c));
}

static bool rec_addr_eq(const bridge_scan_rec_t *a, uint8_t addr_type,
                        const uint8_t *addr)
{
    return a->used && a->addr_type == addr_type &&
           memcmp(a->addr, addr, BRIDGE_BLE_ADDR_LEN) == 0;
}

bridge_scan_rec_t *bridge_ble_scan_cache_update(bridge_scan_cache_t *c,
                                                const bridge_scan_rec_t *in)
{
    bridge_scan_rec_t *slot = NULL;

    for (uint8_t i = 0; i < c->count; i++) {
        if (rec_addr_eq(&c->recs[i], in->addr_type, in->addr)) {
            slot = &c->recs[i];
            break;
        }
    }
    if (slot == NULL) {
        if (c->count < BRIDGE_BLE_SCAN_CACHE_MAX) {
            slot = &c->recs[c->count];
            c->count++;
        } else {
            /* evict the weakest signal; with DK-scale device counts this
             * path is a formality, but it must not degrade into a leak */
            slot = &c->recs[0];
            for (uint8_t i = 1; i < c->count; i++) {
                if (c->recs[i].rssi < slot->rssi) {
                    slot = &c->recs[i];
                }
            }
        }
        *slot = *in;
        slot->used = true;
        return slot;
    }

    slot->rssi = in->rssi;
    if (in->name[0] != '\0') {
        memcpy(slot->name, in->name, sizeof(slot->name));
    }
    if (in->has_fef5) {
        slot->has_fef5 = true; /* sticky: seen once, connectable */
    }
    return slot;
}

const bridge_scan_rec_t *bridge_ble_scan_cache_find_addr(
    const bridge_scan_cache_t *c, uint8_t addr_type,
    const uint8_t addr[BRIDGE_BLE_ADDR_LEN])
{
    for (uint8_t i = 0; i < c->count; i++) {
        if (rec_addr_eq(&c->recs[i], addr_type, addr)) {
            return &c->recs[i];
        }
    }
    return NULL;
}

const bridge_scan_rec_t *bridge_ble_scan_cache_find_name(
    const bridge_scan_cache_t *c, const char *name)
{
    const bridge_scan_rec_t *best = NULL;
    size_t nlen = strlen(name);

    if (nlen == 0U) {
        return NULL;
    }
    for (uint8_t i = 0; i < c->count; i++) {
        const bridge_scan_rec_t *r = &c->recs[i];

        if (r->name[0] == '\0') {
            continue;
        }
        if (strncmp(r->name, name, nlen) != 0) {
            continue;
        }
        if (best == NULL || r->rssi > best->rssi) {
            best = r;
        }
    }
    return best;
}

/* ---- GATT character map --------------------------------------------------- */

uint16_t bridge_ble_uuid128_prefix(
    const uint8_t val_le[BRIDGE_BLE_UUID128_LEN])
{
    /* val[] is over-the-air little-endian: val[15] is the MSB of the
     * readable form ("8082caa8-..." -> val[14] = 0x82, val[15] = 0x80),
     * so the uuid16 prefix is val[14] | val[15] << 8.  The host sends
     * that same value little-endian (suota.py uuid16_le), i.e. the wire
     * bytes match val[14], val[15] in order. */
    return (uint16_t)((uint16_t)val_le[14] | ((uint16_t)val_le[15] << 8));
}

void bridge_ble_char_map_clear(bridge_char_map_t *m)
{
    memset(m, 0, sizeof(*m));
}

int bridge_ble_char_map_add(bridge_char_map_t *m, uint16_t uuid16,
                            uint16_t value_handle, uint16_t ccc_handle,
                            uint8_t props)
{
    for (uint8_t i = 0; i < m->count; i++) {
        if (m->ents[i].uuid16 == uuid16) {
            return 0; /* idempotent */
        }
    }
    if (m->count >= BRIDGE_BLE_CHAR_MAX) {
        return -1;
    }
    m->ents[m->count].uuid16 = uuid16;
    m->ents[m->count].value_handle = value_handle;
    m->ents[m->count].ccc_handle = ccc_handle;
    m->ents[m->count].props = props;
    m->count++;
    return 0;
}

bool bridge_ble_char_map_find(const bridge_char_map_t *m, uint16_t uuid16,
                              bridge_char_ent_t *out)
{
    for (uint8_t i = 0; i < m->count; i++) {
        if (m->ents[i].uuid16 == uuid16) {
            *out = m->ents[i];
            return true;
        }
    }
    return false;
}

/* ---- advertising intent state machine -------------------------------------- */

bridge_adv_act_t bridge_ble_adv_intent_step(bool *wanted,
                                            bridge_adv_evt_t evt)
{
    switch (evt) {
    case BRIDGE_ADV_EV_START:
        *wanted = true;
        break;
    case BRIDGE_ADV_EV_STOP:
        *wanted = false;
        break;
    case BRIDGE_ADV_EV_LINK_LOST:
        /* restart only what the user asked for (and did not explicitly
         * stop); the state itself stays set so later link losses keep
         * recovering */
        return *wanted ? BRIDGE_ADV_ACT_RESTART : BRIDGE_ADV_ACT_NONE;
    }
    return BRIDGE_ADV_ACT_NONE;
}

/* ---- event payload builders ------------------------------------------------ */

int bridge_ble_evt_scan_build(const bridge_scan_rec_t *rec,
                              const uint8_t *adv, size_t adv_len,
                              uint8_t *out, size_t cap)
{
    /* v1.4.1 (E2-T): 1B adv_type inserted after rssi, before the adv TLV. */
    const size_t need = (size_t)1U + 1U + BRIDGE_BLE_ADDR_LEN + 1U + 1U + adv_len;

    if (cap < need) {
        return -(int)need;
    }
    out[0] = 0x00; /* subtype */
    out[1] = rec->addr_type;
    /* v1.4.2: addr is packed in display order (left-to-right as a phone
     * shows it); Zephyr's bt_addr val is little-endian, reverse on the way
     * out.  The scan cache keeps storing val order internally. */
    for (unsigned int i = 0U; i < BRIDGE_BLE_ADDR_LEN; i++) {
        out[2 + i] = rec->addr[BRIDGE_BLE_ADDR_LEN - 1U - i];
    }
    out[8] = (uint8_t)rec->rssi;
    out[9] = rec->adv_type;
    if (adv_len > 0U) {
        memcpy(&out[10], adv, adv_len);
    }
    return (int)need;
}

int bridge_ble_evt_conn_build(uint8_t role, uint8_t addr_type,
                              const uint8_t addr[BRIDGE_BLE_ADDR_LEN],
                              uint8_t *out, size_t cap)
{
    const size_t need = (size_t)1U + 1U + 1U + BRIDGE_BLE_ADDR_LEN;

    if (cap < need) {
        return -(int)need;
    }
    out[0] = 0x00; /* subtype */
    out[1] = role; /* 0 = central role, 1 = peripheral role (FR-H) */
    out[2] = addr_type;
    /* v1.4.2: display order on the wire (see evt_scan_build). */
    for (unsigned int i = 0U; i < BRIDGE_BLE_ADDR_LEN; i++) {
        out[3 + i] = addr[BRIDGE_BLE_ADDR_LEN - 1U - i];
    }
    return (int)need;
}

int bridge_ble_evt_disc_build(uint8_t role, uint8_t reason, uint8_t *out,
                              size_t cap)
{
    if (cap < 3U) {
        return -3;
    }
    out[0] = 0x00; /* subtype */
    out[1] = role; /* 0 = central role, 1 = peripheral role (FR-H) */
    out[2] = reason;
    return 3;
}

int bridge_ble_evt_gattx_build(uint16_t uuid16, const uint8_t *data,
                               size_t len, uint8_t *out, size_t cap)
{
    const size_t need = (size_t)1U + 2U + len;

    if (cap < need) {
        return -(int)need;
    }
    out[0] = 0x00; /* subtype 0x00 = notification */
    bridge_ble_put_le16(&out[1], uuid16);
    if (len > 0U) {
        memcpy(&out[3], data, len);
    }
    return (int)need;
}

int bridge_ble_evt_gattx_write_build(uint16_t uuid16, uint16_t handle,
                                     const uint8_t *data, size_t len,
                                     uint8_t *out, size_t cap)
{
    const size_t need = (size_t)1U + 2U + 2U + len;

    if (cap < need) {
        return -(int)need;
    }
    out[0] = 0x01; /* subtype 0x01 = peripheral-role write (FR-H) */
    bridge_ble_put_le16(&out[1], uuid16);
    bridge_ble_put_le16(&out[3], handle);
    if (len > 0U) {
        memcpy(&out[5], data, len);
    }
    return (int)need;
}

int bridge_ble_evt_mtu_build(uint16_t mtu, uint8_t *out, size_t cap)
{
    if (cap < 3U) {
        return -3;
    }
    out[0] = 0x00; /* subtype */
    bridge_ble_put_le16(&out[1], mtu);
    return 3;
}
```
